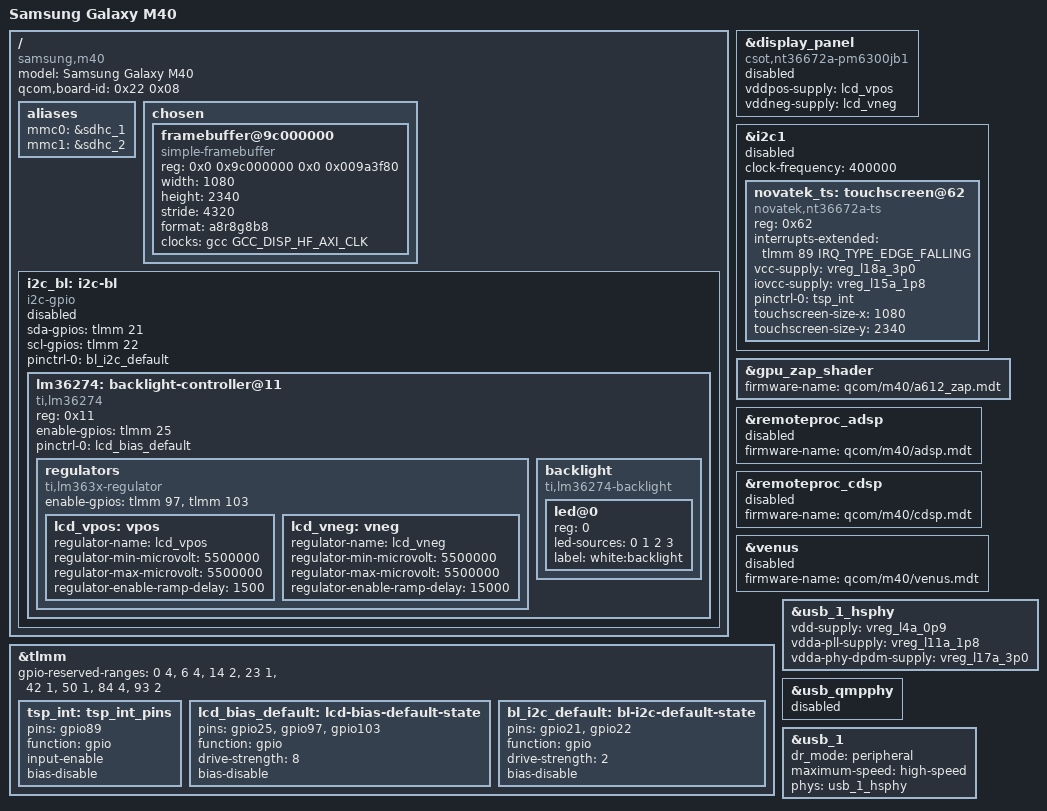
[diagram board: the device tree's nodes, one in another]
// SPDX-License-Identifier: GPL-2.0-only

/dts-v1/;

#include "sm6150-samsung-common.dtsi"

/ {
	model = "Samsung Galaxy M40";
	compatible = "samsung,m40", "qcom,qcs615", "qcom,sm6150";
	qcom,board-id = <0x22 0x08>;


	aliases {
		mmc0 = &sdhc_1;
		mmc1 = &sdhc_2;
	};

	chosen {
		#address-cells = <2>;
		#size-cells = <2>;

		framebuffer@9c000000 {
			compatible = "simple-framebuffer";
			reg = <0x0 0x9c000000 0x0 0x009a3f80>;
			width = <1080>;
			height = <2340>;
			stride = <4320>;
			/* Confirm pixel order and stride against the bootloader framebuffer. */
			format = "a8r8g8b8";
			clocks = <&gcc GCC_DISP_HF_AXI_CLK>;
		};
	};

	i2c_bl: i2c-bl {
		compatible = "i2c-gpio";
		sda-gpios = <&tlmm 21 (GPIO_ACTIVE_HIGH | GPIO_OPEN_DRAIN)>;
		scl-gpios = <&tlmm 22 (GPIO_ACTIVE_HIGH | GPIO_OPEN_DRAIN)>;
		pinctrl-names = "default";
		pinctrl-0 = <&bl_i2c_default>;
		#address-cells = <1>;
		#size-cells = <0>;
		status = "disabled";

	};

};

&i2c_bl {                                  /* i2c-gpio node on tlmm 21/22 */
	lm36274: backlight-controller@11 {
		compatible = "ti,lm36274";
		reg = <0x11>;
		#address-cells = <1>;
		#size-cells = <0>;

		enable-gpios = <&tlmm 25 GPIO_ACTIVE_HIGH>;      /* HWEN */
		pinctrl-names = "default";
		pinctrl-0 = <&lcd_bias_default>;                 /* gpio 25, 97, 103 */

		regulators {
			compatible = "ti,lm363x-regulator";
			#address-cells = <1>;
			#size-cells = <0>;

			enable-gpios = <&tlmm 97 GPIO_ACTIVE_HIGH>,   /* ENP -> vpos */
				       <&tlmm 103 GPIO_ACTIVE_HIGH>;  /* ENN -> vneg */

			lcd_vpos: vpos {
				regulator-name = "lcd_vpos";
				regulator-min-microvolt = <5500000>;
				regulator-max-microvolt = <5500000>;
				regulator-enable-ramp-delay = <1500>;
			};

			lcd_vneg: vneg {
				regulator-name = "lcd_vneg";
				regulator-min-microvolt = <5500000>;
				regulator-max-microvolt = <5500000>;
				regulator-enable-ramp-delay = <15000>;
			};
			/* no vboost node: Samsung never programs it, keep the default */
		};

		backlight {
			compatible = "ti,lm36274-backlight";
			#address-cells = <1>;
			#size-cells = <0>;

			led@0 {
				reg = <0>;
				led-sources = <0 1 2 3>;          /* BL_EN write = 0x1F */
				label = "white:backlight";
			};
		};
	};
};

&display_panel {
	compatible = "csot,nt36672a-pm6300jb1";
	vddpos-supply = <&lcd_vpos>;         /* LM36274 vpos, ENP tlmm 97 */
	vddneg-supply = <&lcd_vneg>;         /* LM36274 vneg, ENN tlmm 103 */

	status = "disabled";
};

&i2c1 {
	status = "disabled";
	clock-frequency = <400000>;

	novatek_ts: touchscreen@62 {
		compatible = "novatek,nt36672a-ts";
		reg = <0x62>;
		interrupts-extended = <&tlmm 89 IRQ_TYPE_EDGE_FALLING>;
		vcc-supply = <&vreg_l18a_3p0>;
		iovcc-supply = <&vreg_l15a_1p8>;
		pinctrl-names = "default";
		pinctrl-0 = <&tsp_int>;
		touchscreen-size-x = <1080>;
		touchscreen-size-y = <2340>;

};

};

&gpu_zap_shader {
	firmware-name = "qcom/m40/a612_zap.mdt";
};

&remoteproc_adsp {
	status = "disabled";
	firmware-name = "qcom/m40/adsp.mdt";
};

&remoteproc_cdsp {
	status = "disabled";
	firmware-name = "qcom/m40/cdsp.mdt";
};

&venus {
	status = "disabled";
	firmware-name = "qcom/m40/venus.mdt";
};

&tlmm {
	/*
	 * Bring-up superset of pins owned by peripherals that may be
	 * TZ-controlled (fingerprint 42/93/94, NFC 84-86/50, ...).
	 * NOT confirmed protected: delete and retest once the board boots.
	 * Pins 0-3 are deliberately not listed (SE0 may be the debug UART).
	 */
	gpio-reserved-ranges = <0 4>, <6 4>, <14 2>, <23 1>, <42 1>, <50 1>, <84 4>, <93 2>;

	tsp_int: tsp_int_pins {
		pins = "gpio89";   /* INT */
		function = "gpio";
		input-enable;
		bias-disable;
	};

	lcd_bias_default: lcd-bias-default-state {
		pins = "gpio25", "gpio97", "gpio103";   /* HWEN, ENP, ENN */
		function = "gpio";
		drive-strength = <8>;
		bias-disable;
	};

	bl_i2c_default: bl-i2c-default-state {
		pins = "gpio21", "gpio22";
		function = "gpio";
		drive-strength = <2>;
		bias-disable;
	};
};

&usb_1_hsphy {
	vdd-supply = <&vreg_l4a_0p9>;
	vdda-pll-supply = <&vreg_l11a_1p8>;
	vdda-phy-dpdm-supply = <&vreg_l17a_3p0>;
	status = "okay";
};

&usb_qmpphy {
	status = "disabled";
};

&usb_1 {
	dr_mode = "peripheral";
	maximum-speed = "high-speed";
	phys = <&usb_1_hsphy>;
	phy-names = "usb2-phy";
	status = "okay";
};
